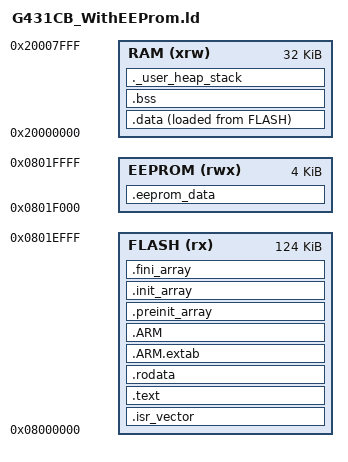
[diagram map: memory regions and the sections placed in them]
ENTRY(Reset_Handler)

_estack = 0x20000000 + 32K;
_Min_Heap_Size = 0x200;
_Min_Stack_Size = 0x400;
_EEPROM_Size = 4K;

MEMORY
{
    FLASH (rx)      : ORIGIN = 0x8000000, LENGTH = 128K - _EEPROM_Size
    RAM (xrw)       : ORIGIN = 0x20000000, LENGTH = 32K
    EEPROM(rwx)	    : ORIGIN = 0x8020000-_EEPROM_Size, LENGTH = _EEPROM_Size
}

SECTIONS
{
  .isr_vector :
  {
    . = ALIGN(4);
    KEEP(*(.isr_vector))
    . = ALIGN(4);
  } >FLASH

  .text :
  {
    . = ALIGN(4);
    *(.text)
    *(.text*)
    *(.glue_7)
    *(.glue_7t)
    *(.eh_frame)
    *(.data.__global_locale) /* move newlib locale into FLASH. See https://bugs.launchpad.net/gcc-arm-embedded/+bug/1686067 */

    KEEP (*(.init))
    KEEP (*(.fini))

    . = ALIGN(4);
    _etext = .;
  } >FLASH

  .rodata :
  {
    . = ALIGN(4);
    *(.rodata)
    *(.rodata*)
    . = ALIGN(4);
  } >FLASH

  .ARM.extab   : { *(.ARM.extab* .gnu.linkonce.armextab.*) } >FLASH
  .ARM : {
    __exidx_start = .;
    *(.ARM.exidx*)
    __exidx_end = .;
  } >FLASH

  .preinit_array     :
  {
    PROVIDE_HIDDEN (__preinit_array_start = .);
    KEEP (*(.preinit_array*))
    PROVIDE_HIDDEN (__preinit_array_end = .);
  } >FLASH
  .init_array :
  {
    PROVIDE_HIDDEN (__init_array_start = .);
    KEEP (*(SORT(.init_array.*)))
    KEEP (*(.init_array*))
    PROVIDE_HIDDEN (__init_array_end = .);
  } >FLASH
  .fini_array :
  {
    PROVIDE_HIDDEN (__fini_array_start = .);
    KEEP (*(SORT(.fini_array.*)))
    KEEP (*(.fini_array*))
    PROVIDE_HIDDEN (__fini_array_end = .);
  } >FLASH

  _sidata = LOADADDR(.data);

  .data : 
  {
    . = ALIGN(4);
    _sdata = .; 
    *(.data)
    *(.data*)

    . = ALIGN(4);
    _edata = .;
  } >RAM AT> FLASH

  . = ALIGN(4);
  .bss :
  {
    _sbss = .;
    __bss_start__ = _sbss;
    *(.bss)
    *(.bss*)
    *(COMMON)

    . = ALIGN(4);
    _ebss = .;
    __bss_end__ = _ebss;
  } >RAM

  ._user_heap_stack :
  {
    . = ALIGN(8);
    PROVIDE ( end = . );
    PROVIDE ( _end = . );
    . = . + _Min_Heap_Size;
    . = . + _Min_Stack_Size;
    . = ALIGN(8);
  } >RAM

  .eeprom_data (NOLOAD) :
  {
      __eeprom_start = .;
    . = ALIGN(4);
    KEEP(*(.isr_vector))
    . = ALIGN(4);
  } >EEPROM

  /DISCARD/ :
  {
    libc.a ( * )
    libm.a ( * )
    libgcc.a ( * )
  }

  .ARM.attributes 0 : { *(.ARM.attributes) }
}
